# M3U0 register map
File version: 0.1
Registers are 32-bit, read-write, no defined reset value unless marked. A register's access mark holds for its fields unless they carry their own. Offsets are from the block's base; [hi:lo] are bit positions; {n}, {i} and the like mark numbered series.

## AMP — Ope-AMP control
Base 0x40030400
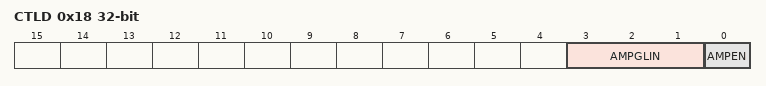
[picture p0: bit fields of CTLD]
0x18 CTLD — Amp D Register
  [3:1] AMPGLIN, [0] AMPEN

## WD — Watchdog Timer (WD)
Base 0x40040000
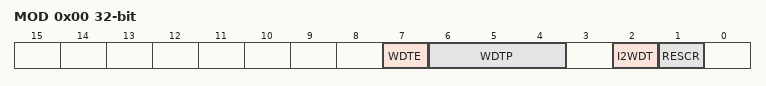
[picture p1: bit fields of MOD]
0x00 MOD — WD Mode Register
  [7] WDTE, [6:4] WDTP, [2] I2WDT, [1] RESCR
0x04 CR wo — WD Control Register
  [7:0] WDCR

## CG — Clock Generator (CG)
Base 0x40040200
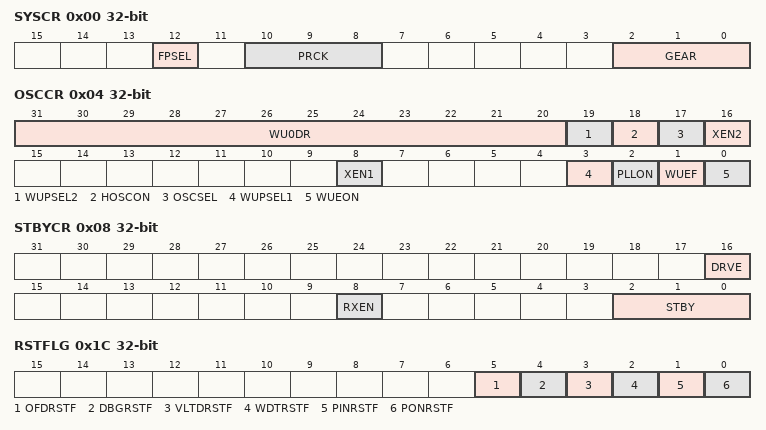
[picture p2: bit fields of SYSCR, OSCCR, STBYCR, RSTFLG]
0x00 SYSCR — System Control Register
  [12] FPSEL, [10:8] PRCK, [2:0] GEAR
0x04 OSCCR — Oscillation Control Register
  [31:20] WU0DR, [19] WUPSEL2, [18] HOSCON, [17] OSCSEL, [16] XEN2, [8] XEN1, [3] WUPSEL1, [2] PLLON, [1] WUEF ro, [0] WUEON wo
0x08 STBYCR — Standby Control Register
  [16] DRVE, [8] RXEN, [2:0] STBY
0x0C PLLSEL — PLL Selection Register
  [0] PLLSEL
0x14 ICRCG wo — CG Interrupt Request Clear Register
  [4:0] ICRCG
0x18 NMIFLG ro — NMI Flag Register
  [0] NMIFLG0
0x1C RSTFLG — Reset Flag Register
  [5] OFDRSTF, [4] DBGRSTF, [3] VLTDRSTF, [2] WDTRSTF, [1] PINRSTF, [0] PONRSTF
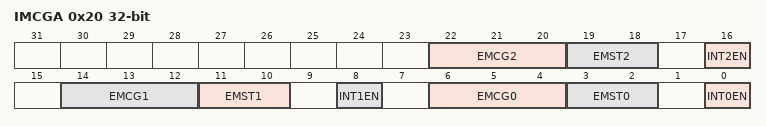
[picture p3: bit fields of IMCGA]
0x20 IMCGA — CG Interrupt Mode Control Register A
  [22:20] EMCG2, [19:18] EMST2 ro, [16] INT2EN, [14:12] EMCG1, [11:10] EMST1 ro, [8] INT1EN, [6:4] EMCG0, [3:2] EMST0 ro, [0] INT0EN

## TRMOSC — Internal High-speed Oscillation Adjustment
Base 0x40040300
0x00 PRO — Protect Register
  [7:0] PROTECT
0x04 EN — Enable reegister
  [0] TRIMEN
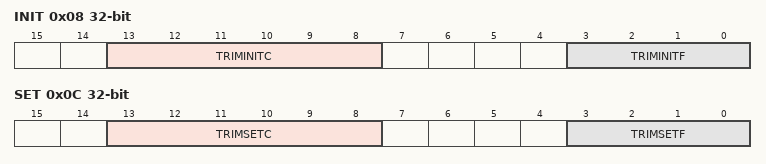
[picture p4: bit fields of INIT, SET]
0x08 INIT ro — Initial Value MonitorRegister
  [13:8] TRIMINITC, [3:0] TRIMINITF
0x0C SET — Setting Register
  [13:8] TRIMSETC, [3:0] TRIMSETF

## OFD — Oscillation Frequency Detector (OFD)
Base 0x40040800
0x00 CR1 — OFD Control Register 1
  [7:0] OFDWEN
0x04 CR2 — OFD Control Register 2
  [7:0] OFDEN
0x08 MNPLLOFF — OFD Lower Detection Frequency Setting Register
  [8:0] OFDMNPLLOFF
0x0C MNPLLON — OFD Lower Detection Frequency Setting Register
  [8:0] OFDMNPLLON
0x10 MXPLLOFF — OFD Higher Detection Frequency Setting Register
  [8:0] OFDMXPLLOFF
0x14 MXPLLON — OFD Higher Detection Frequency Setting Register
  [8:0] OFDMXPLLON

## VD — Low Voltage Detection Circuit
Base 0x40040900
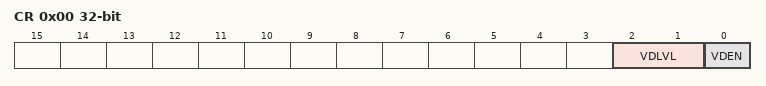
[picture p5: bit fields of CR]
0x00 CR — VD Control Register
  [2:1] VDLVL, [0] VDEN

## PMD — 16-bit Multi-Purpose Timer (MPT-PMD)
Base 0x40050480
0x00 MDEN — PMD Enable Register
  [0] PWMEN
0x04 PORTMD — Port Output Mode Register
  [1:0] PORTMD
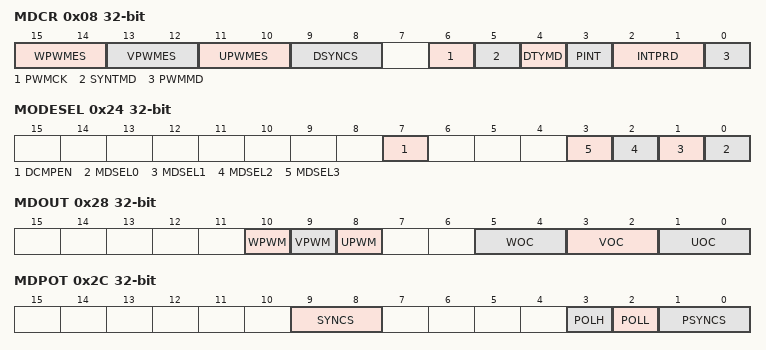
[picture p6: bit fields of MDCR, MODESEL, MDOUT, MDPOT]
0x08 MDCR — PMD Control Register
  [15:14] WPWMES, [13:12] VPWMES, [11:10] UPWMES, [9:8] DSYNCS, [6] PWMCK, [5] SYNTMD, [4] DTYMD, [3] PINT, [2:1] INTPRD, [0] PWMMD
0x0C CNTSTA ro — PWM Counter Status Register
  [0] UPDWN
0x10 MDCNT ro — PWM Counter Register
  [15:0] MDCNT
0x14 MDPRD — PWM Period Register
  [15:0] MDPRD
0x18 CMPU — PWM Compare Register
  [15:0] CMPU1
0x1C CMPV — PWM Compare Register
  [15:0] CMPV1
0x20 CMPW — PWM Compare Register
  [15:0] CMPW1
0x24 MODESEL — PWM Mode Select Register
  [7] DCMPEN, [n] MDSEL{n} (n=0..3)
0x28 MDOUT — PMD Output Control Register
  [10] WPWM, [9] VPWM, [8] UPWM, [5:4] WOC, [3:2] VOC, [1:0] UOC
0x2C MDPOT — PMD Output Setting Register
  [9:8] SYNCS, [3] POLH, [2] POLL, [1:0] PSYNCS
0x30 EMGREL — EMG Release Register
  [7:0] EMGREL wo
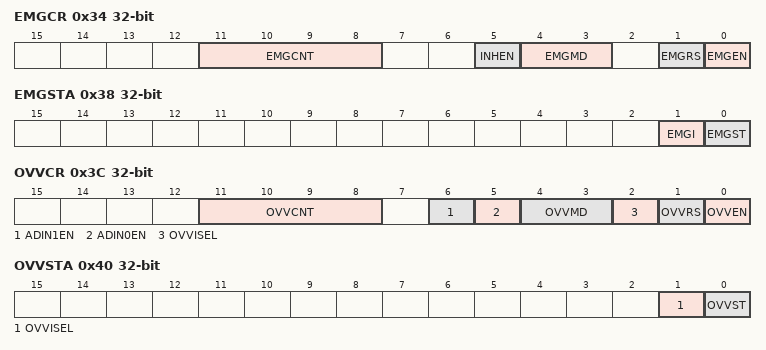
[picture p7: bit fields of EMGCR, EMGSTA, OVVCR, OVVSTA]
0x34 EMGCR — EMG Control Register
  [11:8] EMGCNT, [5] INHEN wo, [4:3] EMGMD, [1] EMGRS wo, [0] EMGEN
0x38 EMGSTA ro — EMG Status Register
  [1] EMGI, [0] EMGST
0x3C OVVCR — OVV Control Register
  [11:8] OVVCNT, [6] ADIN1EN, [5] ADIN0EN, [4:3] OVVMD, [2] OVVISEL, [1] OVVRS, [0] OVVEN
0x40 OVVSTA ro — OVV Status Register
  [1] OVVISEL, [0] OVVST
0x44 DTR — Dead Time Register
  [7:0] DTR
{0x48+4i} TRGCMP{i} (i=0..3) — Trigger Compare Register {i}
  [15:0] TRGCMP{i}
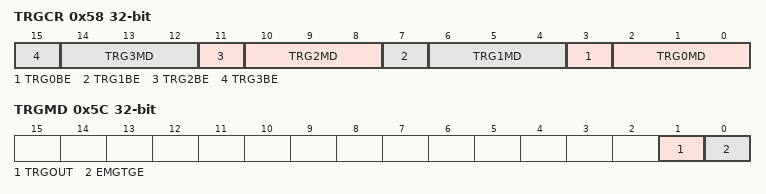
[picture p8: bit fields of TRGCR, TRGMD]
0x58 TRGCR — Trigger Control Register
  [4n+3] TRG{n}BE (n=0..3), [4n+2:4n] TRG{n}MD (n=0..3)
0x5C TRGMD — Trigger Output Mode Setting Register
  [1] TRGOUT, [0] EMGTGE
0x60 TRGSEL — Trigger Output Select Register
  [2:0] TRGSEL
0x64 TRGSYNCR — TriggerReflashSetting Register
  [1:0] TSYNCS

## NF — DigitalNoizeFilterClockControl
Base 0x40060000
0x00 CKCR — Clcok Control
  [2:0] NFCKS
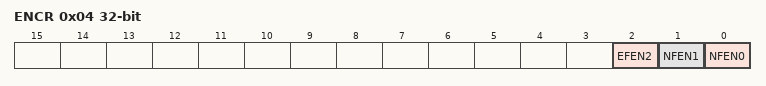
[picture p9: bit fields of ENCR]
0x04 ENCR — EnableControl
  [2] EFEN2, [1] NFEN1, [0] NFEN0

## FC — Flash Control (FC)
Base 0x41FFF010
0x00 SECBIT — FC Security Bit Register
  [0] SECBIT
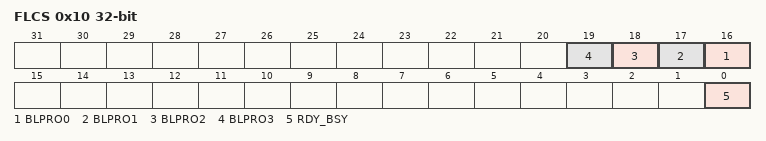
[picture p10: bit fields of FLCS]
0x10 FLCS ro — FC Register
  [n+16] BLPRO{n} (n=0..3), [0] RDY_BSY
0x1C FLCR — Flash Interface Control Register
  [0] FLBOFF
